# CH32V00xxx register map
Vendor: WCH; File version: 2024.09.30
Registers are 32-bit, read-write, reset 0x0 unless marked. A register's access mark holds for its fields unless they carry their own. Offsets are from the block's base; [hi:lo] are bit positions; {n}, {i} and the like mark numbered series.

## I2C1 — Inter integrated circuit
Base 0x40005400
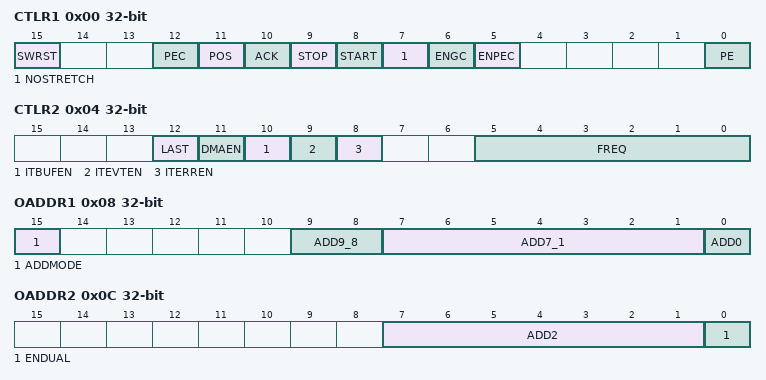
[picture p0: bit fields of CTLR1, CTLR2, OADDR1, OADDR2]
0x00 CTLR1 — Control register 1
  [15] SWRST — Software reset
  [12] PEC — Packet error checking
  [11] POS — Acknowledge/PEC Position (for data reception)
  [10] ACK — Acknowledge enable
  [9] STOP — Stop generation
  [8] START — Start generation
  [7] NOSTRETCH — Clock stretching disable (Slave mode)
  [6] ENGC — General call enable
  [5] ENPEC — PEC enable
  [0] PE — Peripheral enable
0x04 CTLR2 — Control register 2
  [12] LAST — DMA last transfer
  [11] DMAEN — DMA requests enable
  [10] ITBUFEN — Buffer interrupt enable
  [9] ITEVTEN — Event interrupt enable
  [8] ITERREN — Error interrupt enable
  [5:0] FREQ — Peripheral clock frequency
0x08 OADDR1 — Own address register 1
  [15] ADDMODE — Addressing mode (slave mode)
  [9:8] ADD9_8 — Interface address
  [7:1] ADD7_1 — Interface address
  [0] ADD0 — Interface address
0x0C OADDR2 — Own address register 2
  [7:1] ADD2 — Interface address
  [0] ENDUAL — Dual addressing mode enable
0x10 DATAR — Data register
  [7:0] DATAR — 8-bit data register
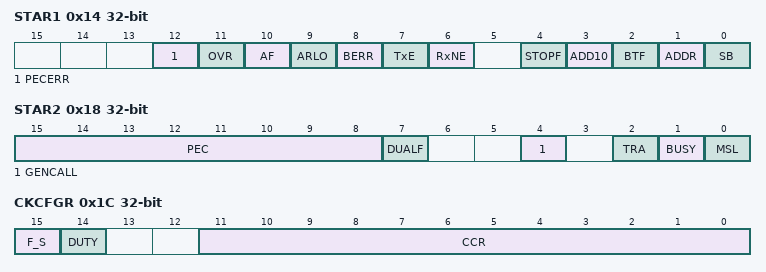
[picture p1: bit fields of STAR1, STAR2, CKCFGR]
0x14 STAR1 access per field — Status register 1
  [12] PECERR rw — PEC Error in reception
  [11] OVR rw — Overrun/Underrun
  [10] AF rw — Acknowledge failure
  [9] ARLO rw — Arbitration lost (master mode)
  [8] BERR rw — Bus error
  [7] TxE ro — Data register empty (transmitters)
  [6] RxNE ro — Data register not empty (receivers)
  [4] STOPF ro — Stop detection (slave mode)
  [3] ADD10 ro — 10-bit header sent (Master mode)
  [2] BTF ro — Byte transfer finished
  [1] ADDR ro — Address sent (master mode)/matched (slave mode)
  [0] SB ro — Start bit (Master mode)
0x18 STAR2 ro — Status register 2
  [15:8] PEC — acket error checking register
  [7] DUALF — Dual flag (Slave mode)
  [4] GENCALL — General call address (Slave mode)
  [2] TRA — Transmitter/receiver
  [1] BUSY — Bus busy
  [0] MSL — Master/slave
0x1C CKCFGR — Clock control register
  [15] F_S — I2C master mode selection
  [14] DUTY — Fast mode duty cycle
  [11:0] CCR — Clock control register in Fast/Standard mode (Master mode)

## IWDG — Independent watchdog
Base 0x40003000
0x00 CTLR wo — Key register (IWDG_CTLR)
  [15:0] KEY — Key value
0x04 PSCR — Prescaler register (IWDG_PSCR)
  [2:0] PR — Prescaler divider
0x08 RLDR reset 0xFFF — Reload register (IWDG_RLDR)
  [11:0] RL — Watchdog counter reload value
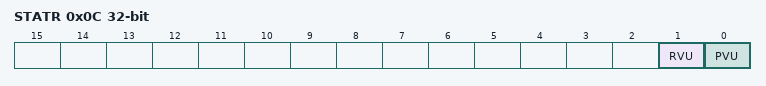
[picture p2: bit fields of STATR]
0x0C STATR ro — Status register (IWDG_SR)
  [1] RVU — Watchdog counter reload value update
  [0] PVU — Watchdog prescaler value update

## PFIC — Programmable Fast Interrupt Controller
Base 0xE000E000
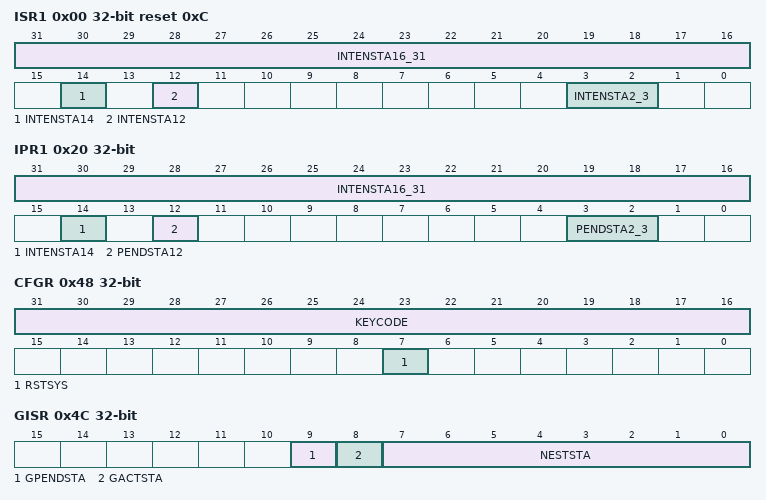
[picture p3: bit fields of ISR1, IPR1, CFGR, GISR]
0x00 ISR1 ro reset 0xC — Interrupt Status Register
  [31:16] INTENSTA16_31 — Interrupt ID Status
  [14] INTENSTA14 — Interrupt ID Status
  [12] INTENSTA12 — Interrupt ID Status
  [3:2] INTENSTA2_3 — Interrupt ID Status
0x04 ISR2 ro — Interrupt Status Register
  [6:0] INTENSTA — Interrupt ID Status
0x20 IPR1 ro — Interrupt Pending Register
  [31:16] INTENSTA16_31 — PENDSTA
  [14] INTENSTA14 — PENDSTA
  [12] PENDSTA12 — PENDSTA
  [3:2] PENDSTA2_3 — PENDSTA
0x24 IPR2 ro — Interrupt Pending Register
  [6:0] PENDSTA32_38 — PENDSTA
0x40 ITHRESDR — Interrupt Priority Register
  [7:0] THRESHOLD
0x48 CFGR wo — Interrupt Config Register
  [31:16] KEYCODE
  [7] RSTSYS — RESET System
0x4C GISR ro — Interrupt Global Register
  [9] GPENDSTA, [8] GACTSTA, [7:0] NESTSTA
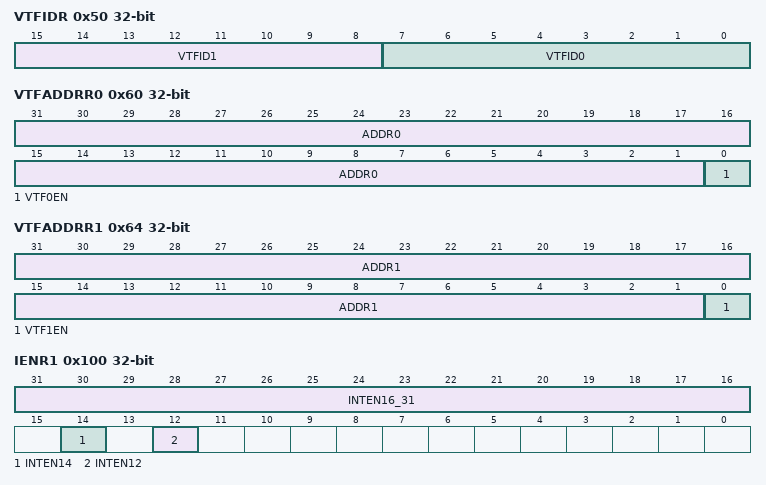
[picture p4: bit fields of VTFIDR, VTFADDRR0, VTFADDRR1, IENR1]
0x50 VTFIDR — ID Config Register
  [15:8] VTFID1, [7:0] VTFID0
0x60 VTFADDRR0 — Interrupt 0 address Register
  [31:1] ADDR0, [0] VTF0EN
0x64 VTFADDRR1 — Interrupt 1 address Register
  [31:1] ADDR1, [0] VTF1EN
0x100 IENR1 wo — Interrupt Setting Register
  [31:16] INTEN16_31, [14] INTEN14, [12] INTEN12
0x104 IENR2 wo — Interrupt Setting Register
  [6:0] INTEN — INTEN32_38
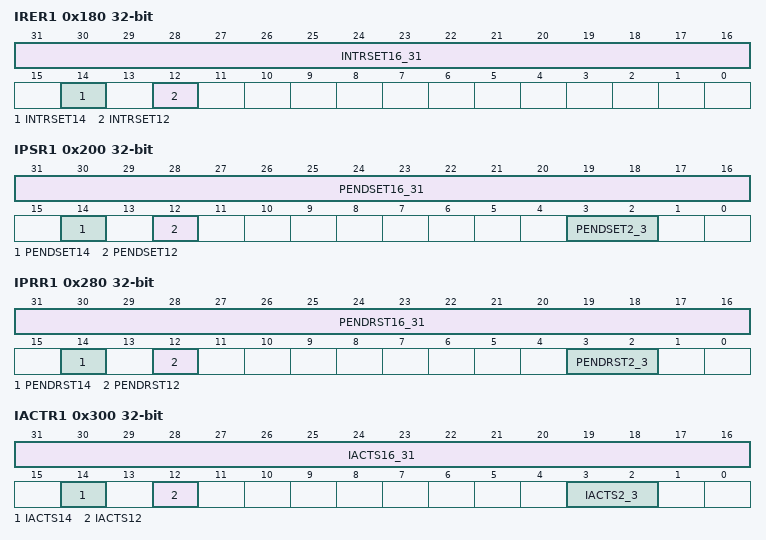
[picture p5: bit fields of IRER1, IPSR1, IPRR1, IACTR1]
0x180 IRER1 wo — Interrupt Clear Register
  [31:16] INTRSET16_31, [14] INTRSET14, [12] INTRSET12
0x184 IRER2 wo — Interrupt Clear Register
  [6:0] INTRSET38_32
0x200 IPSR1 wo — Interrupt Pending Register
  [31:16] PENDSET16_31 — PENDSET
  [14] PENDSET14 — PENDSET
  [12] PENDSET12 — PENDSET
  [3:2] PENDSET2_3 — PENDSET
0x204 IPSR2 wo — Interrupt Pending Register
  [6:0] PENDSET32_38
0x280 IPRR1 wo — Interrupt Pending Clear Register
  [31:16] PENDRST16_31 — PENDRESET
  [14] PENDRST14 — PENDRESET
  [12] PENDRST12 — PENDRESET
  [3:2] PENDRST2_3 — PENDRESET
0x284 IPRR2 wo — Interrupt Pending Clear Register
  [6:0] PENDRST32_38 — PENDRESET32_38
0x300 IACTR1 wo — Interrupt ACTIVE Register
  [31:16] IACTS16_31 — IACTS
  [14] IACTS14 — IACTS
  [12] IACTS12 — IACTS
  [3:2] IACTS2_3 — IACTS
0x304 IACTR2 wo — Interrupt ACTIVE Register
  [6:0] IACTS
{0x400+i} IPRIOR{i} 8-bit (i=0..63) — Interrupt Priority Register
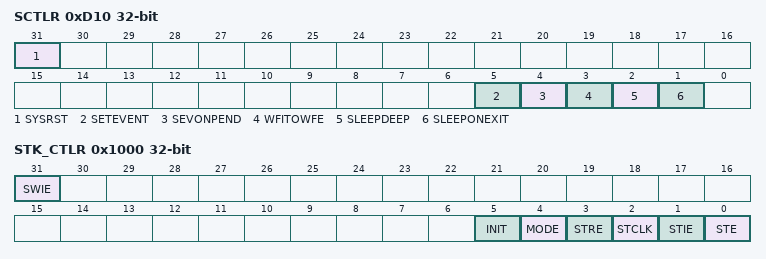
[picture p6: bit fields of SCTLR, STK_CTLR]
0xD10 SCTLR — System Control Register
  [31] SYSRST — SYSRESET
  [5] SETEVENT
  [4] SEVONPEND
  [3] WFITOWFE
  [2] SLEEPDEEP
  [1] SLEEPONEXIT
0x1000 STK_CTLR — System counter control register
  [31] SWIE — System software triggered interrupts enable
  [5] INIT — System Initialization update
  [4] MODE — System Mode
  [3] STRE — System reload register
  [2] STCLK — System selects the clock source
  [1] STIE — System counter interrupt enable
  [0] STE — System counter enable
0x1004 STK_SR — System START
  [0] CNTIF
0x1008 STK_CNTL — System counter low register
  [31:0] CNT
0x1010 STK_CMPLR — System compare low register
  [31:0] CMP
